# EFR32FG22C121F512GM32 register map
Vendor: Silicon Labs; Series: EFR32; File version: C
Registers are 32-bit, read-write, reset 0x0 unless marked. A register's access mark holds for its fields unless they carry their own. Offsets are from the block's base; [hi:lo] are bit positions; {n}, {i} and the like mark numbered series; 'fields as' and 'values as' point back to an identical list.

## CRYPTOACC_S_PKCTRL — CRYPTOACC_S_PKCTRL Registers
Base 0x4C022000
Same registers: CRYPTOACC_NS_PKCTRL 0x5C022000
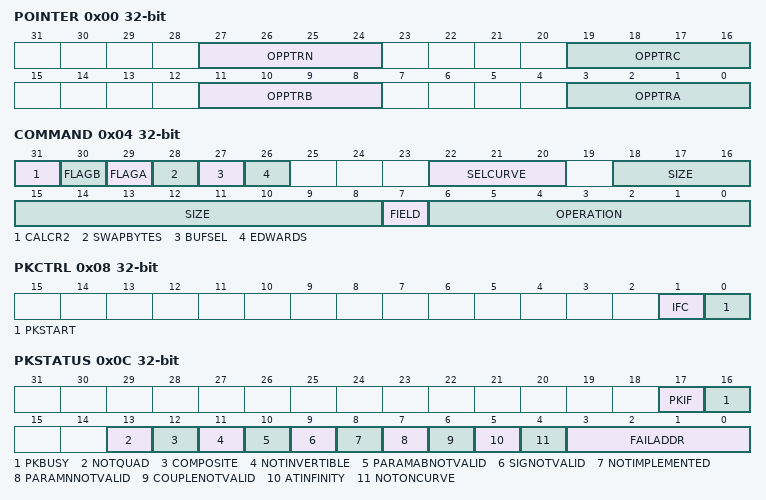
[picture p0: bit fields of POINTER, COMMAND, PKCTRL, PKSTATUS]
0x00 POINTER
  [27:24] OPPTRN, [19:16] OPPTRC, [11:8] OPPTRB, [3:0] OPPTRA
0x04 COMMAND
  [31] CALCR2 — Calculate R2
    0=FALSE (don't recalculate R² mod N); 1=TRUE (re-calculate R² mod N)
  [30] FLAGB
  [29] FLAGA
  [28] SWAPBYTES
    0=NATIVE (Native format (little endian)); 1=SWAPPED (Byte swapped (big endian))
  [27] BUFSEL — Buffer Select
    0=MEM0 (use data in data memory 0)
  [26] EDWARDS — Edwards Curve Enable
  [22:20] SELCURVE — Select Curve
    0=NONE (No acceleration); 1=P256; 4=P192
  [18:8] SIZE — Size of Operands in data memory
  [7] FIELD
    0=GFP (Field is GF(p)); 1=GF2M (Field is GF(2^m))
  [6:0] OPERATION — Type of Operation
0x08 PKCTRL wo
  [1] IFC — ClearIRQ
  [0] PKSTART
0x0C PKSTATUS ro
  [17] PKIF — Interrupt status
  [16] PKBUSY
  [13] NOTQUAD — Not quadratic residue
  [12] COMPOSITE
    0=FALSE (random number under test is probably prime); 1=TRUE (random number under test is composite)
  [11] NOTINVERTIBLE
  [10] PARAMABNOTVALID
  [9] SIGNOTVALID — Signature not valid
  [8] NOTIMPLEMENTED
  [7] PARAMNNOTVALID
  [6] COUPLENOTVALID
  [5] ATINFINITY — Point Px at infinity
  [4] NOTONCURVE — Point Px not on curve
  [3:0] FAILADDR — Fail Address
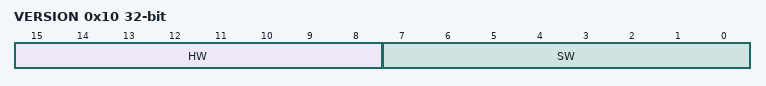
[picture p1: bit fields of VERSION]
0x10 VERSION ro
  [15:8] HW — Hardware version number
  [7:0] SW — Software version number
0x14 TIMER ro

## RFCRC_S — RFCRC_S Registers
Base 0xA8010000
Same registers: RFCRC_NS 0xB8010000
0x00 IPVERSION ro
0x04 EN
  [0] EN — Enable peripheral clock to this module
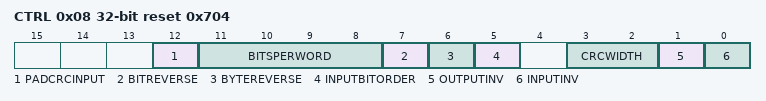
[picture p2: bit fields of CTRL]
0x08 CTRL reset 0x704
  [12] PADCRCINPUT — Pad CRC input data
    0=No zero-padding of CRC input data is applied; 1=CRC input data is zero-padded, such that the number of bytes over which the CRC value is calculated at least equals the length of the calculated CRC value
  [11:8] BITSPERWORD — Number of bits per input word
  [7] BITREVERSE — Reverse CRC bit ordering over air
    0=NORMAL (The bit ordering of CRC data is the same as defined by the BITORDER field in the Frame Controller.); 1=REVERSED (The bit ordering of CRC data is the opposite as defined by the BITORDER field in the Frame Controller.)
  [6] BYTEREVERSE — Reverse CRC byte ordering over air
    0=NORMAL (The least significant byte of the CRC register is transferred first over air via the Frame Controller.); 1=REVERSED (The most significant byte of the CRC register is transferred first over air via the Frame Controller.)
  [5] INPUTBITORDER — CRC input bit ordering setting
    0=LSBFIRST (The least significant data bit is first input to the CRC generator.); 1=MSBFIRST (The most significant data bit is first input to the CRC generator.)
  [3:2] CRCWIDTH
    0=8 bit (1 Byte) CRC code; 1=16 bit (2 Bytes) CRC code; 2=24 bit (3 Bytes) CRC code; 3=32 bit (4 Bytes) CRC code
  [1] OUTPUTINV — Output Invert
  [0] INPUTINV — Input Invert
0x0C STATUS ro
  [0] BUSY — CRC Running
0x10 CMD wo
  [0] INITIALIZE — Initialize CRC
0x14 INPUTDATA wo
  [15:0] INPUTDATA
0x18 INIT
  [31:0] INIT — CRC Initialization Value
0x1C DATA ro
  [31:0] DATA — CRC Data Register
0x20 POLY
  [31:0] POLY — CRC Polynomial Value

## RDMAILBOX0_S — RDMAILBOX0_S Registers
Base 0xA8028000
Same registers: RDMAILBOX1_S 0xA802C000, RDMAILBOX0_NS 0xB8028000, RDMAILBOX1_NS 0xB802C000
{0x0+4i} MSGPTR{i} (i=0..3)
  [31:0] PTR — Pointer
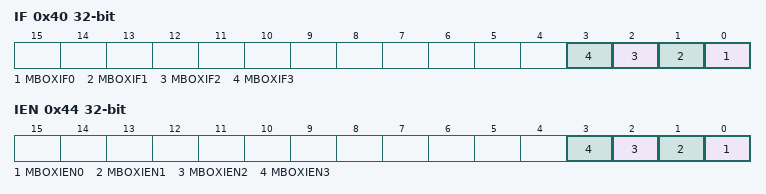
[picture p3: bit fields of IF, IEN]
0x40 IF
  [n] MBOXIF{n} (n=0..3) — Mailbox Interupt Flag
0x44 IEN
  [n] MBOXIEN{n} (n=0..3) — Mailbox Interrupt Enable

## BUFC_S — BUFC_S Registers
Base 0xAA000000
Same registers: BUFC_NS 0xBA000000
0x00 IPVERSION ro reset 0x1
0x04 EN
  [0] EN — Enable peripheral clock to this module
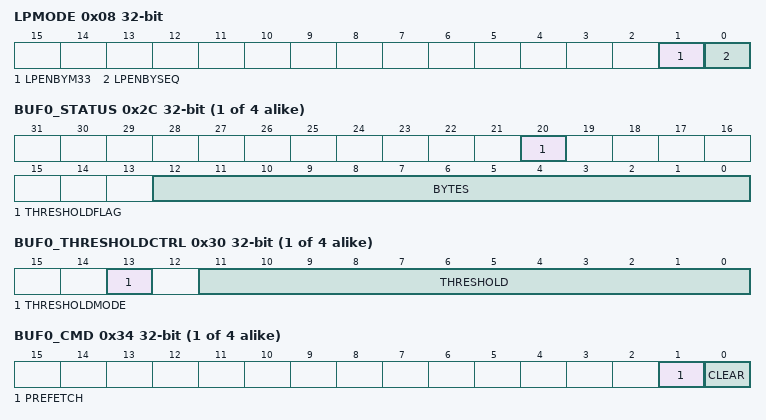
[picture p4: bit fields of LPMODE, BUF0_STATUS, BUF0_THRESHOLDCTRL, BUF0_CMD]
0x08 LPMODE
  [1] LPENBYM33 — Low power mode enable from M33
  [0] LPENBYSEQ — Low power mode enable from M0p sequencer
{0xC+0x40*i} BUF{i}_CTRL (i=0..3)
  [2:0] SIZE — Buffer Size
    0=Sets Buffer size to 64 bytes; 1=Sets Buffer size to 128 bytes; 2=Sets Buffer size to 256 bytes; 3=Sets Buffer size to 512 bytes; 4=Sets Buffer size to 1024 bytes; 5=Sets Buffer size to 2048 bytes; 6=Sets Buffer size to 4096 bytes
{0x10+0x40*i} BUF{i}_ADDR reset 0x20000000 (i=0..3)
  [31:2] ADDR — Buffer Address
{0x14+0x40*i} BUF{i}_WRITEOFFSET (i=0..3)
  [12:0] WRITEOFFSET
{0x18+0x40*i} BUF{i}_READOFFSET (i=0..3)
  [12:0] READOFFSET
{0x20+0x40*i} BUF{i}_READDATA ro (i=0..3)
  [7:0] READDATA — Buffer Read Data
{0x24+0x40*i} BUF{i}_WRITEDATA wo (i=0..3)
  [7:0] WRITEDATA — Buffer Write Data
{0x28+0x40*i} BUF{i}_XWRITE wo (i=0..3)
  [7:0] XORWRITEDATA — Buffer XOR Write Data
{0x2C+0x40*i} BUF{i}_STATUS ro (i=0..3)
  [20] THRESHOLDFLAG — Buffer Threshold Flag
  [12:0] BYTES — Number of Bytes in the Buffer
{0x30+0x40*i} BUF{i}_THRESHOLDCTRL (i=0..3)
  [13] THRESHOLDMODE — Buffer Threshold Mode
    0=LARGER (THRESHOLDIF will be set if BYTES is larger than THRESHOLD); 1=LESSOREQUAL (THRESHOLDIF will be set if BYTES is less than or equal to THRESHOLD)
  [11:0] THRESHOLD — Buffer Threshold Value
{0x34+0x40*i} BUF{i}_CMD wo (i=0..3)
  [1] PREFETCH
  [0] CLEAR — Buffer Clear
{0x38+0x40*i} BUF{i}_FIFOASYNC wo (i=0..3)
  [0] RST — Reset ASYNC
{0x3C+0x40*i} BUF{i}_READDATA32 ro (i=0..3)
  [31:0] READDATA32 — Buffer Read Data
{0x40+0x40*i} BUF{i}_WRITEDATA32 wo (i=0..3)
  [31:0] WRITEDATA32 — Buffer Write Data
{0x44+0x40*i} BUF{i}_XWRITE32 wo (i=0..3)
  [31:0] XORWRITEDATA32 — Buffer XOR Write Data
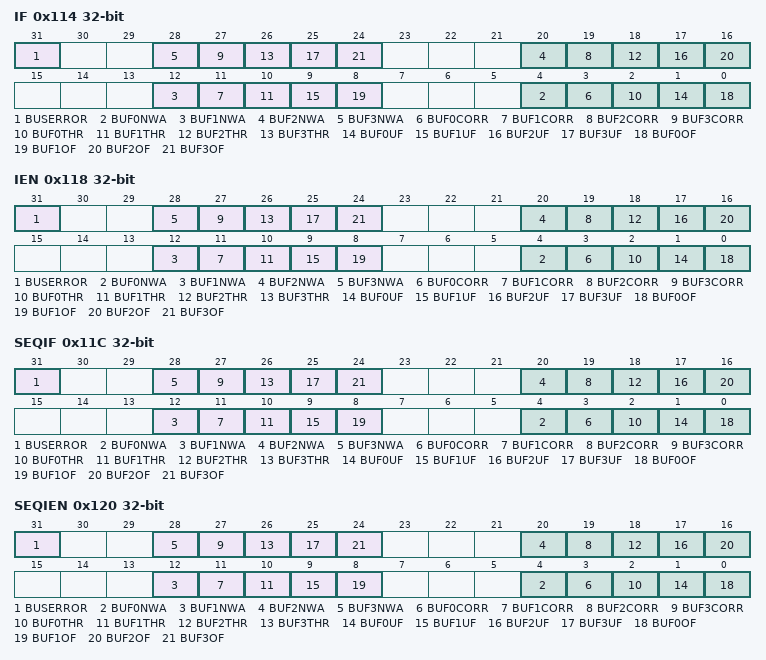
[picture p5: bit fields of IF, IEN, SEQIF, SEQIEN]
0x114 IF
  [31] BUSERROR
  [8n+4] BUF{n}NWA (n=0..3) — Buffer {n} Not Word-Aligned
  [8n+3] BUF{n}CORR (n=0..3) — Buffer {n} Corrupt
  [8n+2] BUF{n}THR (n=0..3) — Buffer {n} Threshold Event
  [8n+1] BUF{n}UF (n=0..3) — Buffer {n} Underflow
  [8n] BUF{n}OF (n=0..3) — Buffer {n} Overflow
0x118 IEN
  [31] BUSERROR — BUSERROR Interrupt Enable
  [8n+4] BUF{n}NWA (n=0..3) — BUF{n}NWA Interrupt Enable
  [8n+3] BUF{n}CORR (n=0..3) — BUF{n}CORR Interrupt Enable
  [8n+2] BUF{n}THR (n=0..3) — BUF{n}THR Interrupt Enable
  [8n+1] BUF{n}UF (n=0..3) — BUF{n}UF Interrupt Enable
  [8n] BUF{n}OF (n=0..3) — BUF{n}OF Interrupt Enable
0x11C SEQIF
  fields as IF
0x120 SEQIEN
  fields as IEN
